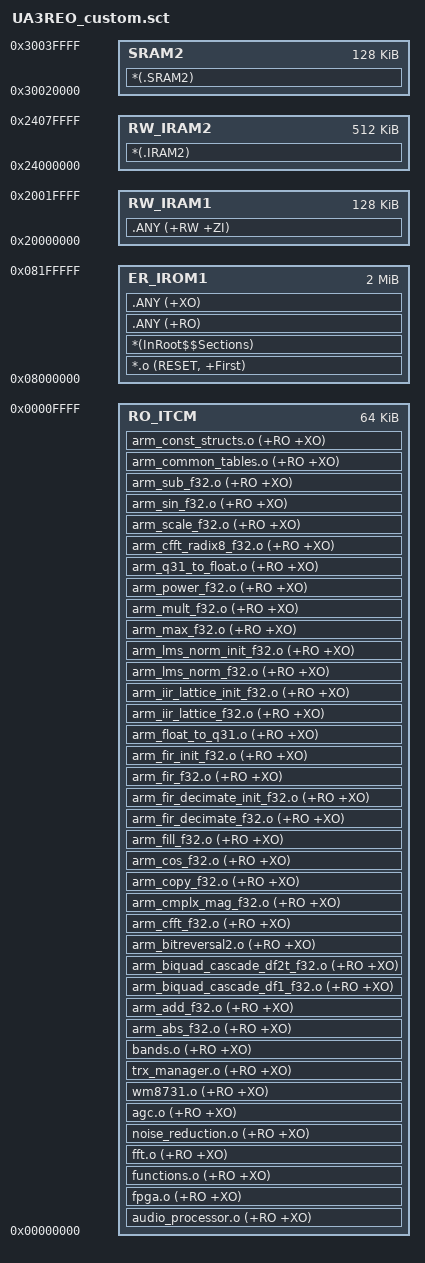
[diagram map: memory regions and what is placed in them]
; *************************************************************
; *** Scatter-Loading Description File generated by uVision ***
; *************************************************************

LR_IROM1 0x08000000 0x00200000  {    ; load region size_region
  ER_IROM1 0x08000000 0x00200000  {  ; load address = execution address ; 2mb FLASH
   *.o (RESET, +First)
   *(InRoot$$Sections)
   .ANY (+RO)
   .ANY (+XO)
  }
  RO_ITCM 0x00000000 0x00010000  { ;64kb ITCM
   ;*(.ITCM)
   audio_processor.o (+RO +XO)
   fpga.o (+RO +XO)
   functions.o (+RO +XO)
   fft.o (+RO +XO)
   noise_reduction.o (+RO +XO)
   agc.o (+RO +XO)
   wm8731.o (+RO +XO)
   trx_manager.o (+RO +XO)
   bands.o (+RO +XO)
   
   arm_abs_f32.o (+RO +XO)
   arm_add_f32.o (+RO +XO)
   arm_biquad_cascade_df1_f32.o (+RO +XO)
   arm_biquad_cascade_df2t_f32.o (+RO +XO)
   arm_bitreversal2.o (+RO +XO)
   arm_cfft_f32.o (+RO +XO)
   arm_cmplx_mag_f32.o (+RO +XO)
   arm_copy_f32.o (+RO +XO)
   arm_cos_f32.o (+RO +XO)
   arm_fill_f32.o (+RO +XO)
   arm_fir_decimate_f32.o (+RO +XO)
   arm_fir_decimate_init_f32.o (+RO +XO)
   arm_fir_f32.o (+RO +XO)
   arm_fir_init_f32.o (+RO +XO)
   arm_float_to_q31.o (+RO +XO)
   arm_iir_lattice_f32.o (+RO +XO)
   arm_iir_lattice_init_f32.o (+RO +XO)
   arm_lms_norm_f32.o (+RO +XO)
   arm_lms_norm_init_f32.o (+RO +XO)
   arm_max_f32.o (+RO +XO)
   arm_mult_f32.o (+RO +XO)
   arm_power_f32.o (+RO +XO)
   arm_q31_to_float.o (+RO +XO)
   arm_cfft_radix8_f32.o (+RO +XO)
   arm_scale_f32.o (+RO +XO)
   arm_sin_f32.o (+RO +XO)
   arm_sub_f32.o (+RO +XO)
   arm_common_tables.o (+RO +XO)
   arm_const_structs.o (+RO +XO)
  }
  RW_IRAM1 0x20000000 0x00020000  {  ;128kb DTCM 
   .ANY (+RW +ZI)
  }
  RW_IRAM2 0x24000000 0x00080000  { ;512kb AXI SRAM
   *(.IRAM2)
   ;.ANY (+RW +ZI)
  }
  ;SRAM1 0x30000000 0x00020000  { ;128kb
   ;*(.SRAM1)
  ;}
  SRAM2 0x30020000 0x00020000  { ;128kb D-Cache disabled in MPU
   *(.SRAM2)
  }
  ;SRAM3 0x30040000 0x00008000  { ;32kb
   ;*(.SRAM3)
  ;}
  ;SRAM4 0x38000000 0x00010000  { ;64kb
   ;*(.SRAM4)
  ;}
  ;BACKUP_SRAM 0x38800000 0x00001000  { ;4kb Backup SRAM
   ;*(.BACKUP_SRAM)
  ;}
}
